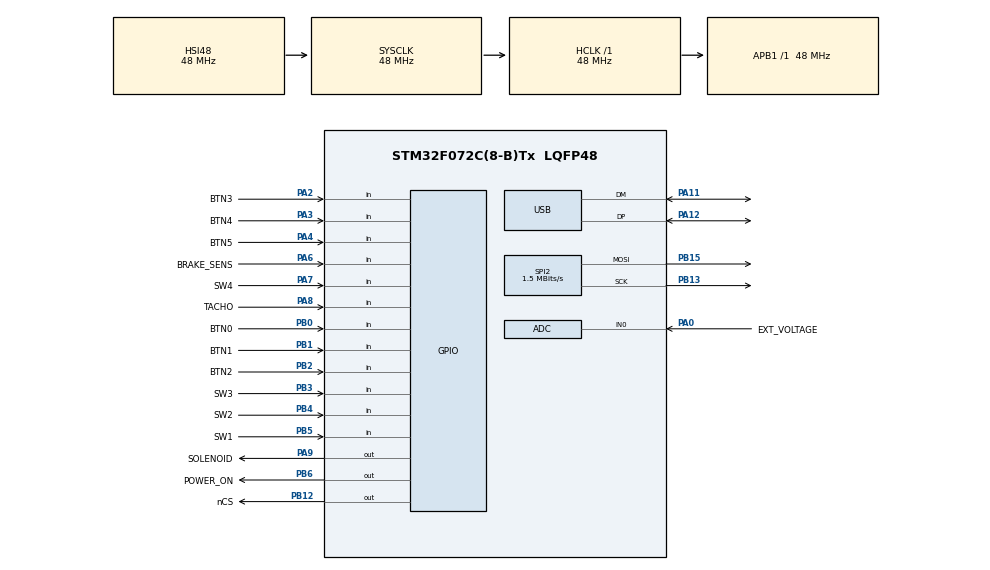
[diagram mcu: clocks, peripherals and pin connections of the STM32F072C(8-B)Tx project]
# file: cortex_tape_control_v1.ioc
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ADC.ClockPrescaler=ADC_CLOCK_ASYNC_DIV1
ADC.ContinuousConvMode=ENABLE
ADC.DMAContinuousRequests=DISABLE
ADC.DiscontinuousConvMode=DISABLE
ADC.EOCSelection=ADC_EOC_SINGLE_CONV
ADC.SamplingTime=ADC_SAMPLETIME_28CYCLES_5
Dma.ADC.0.Direction=DMA_PERIPH_TO_MEMORY
Dma.ADC.0.Instance=DMA1_Channel1
Dma.ADC.0.MemDataAlignment=DMA_MDATAALIGN_HALFWORD
Dma.ADC.0.MemInc=DMA_MINC_ENABLE
Dma.ADC.0.Mode=DMA_CIRCULAR
Dma.ADC.0.PeriphDataAlignment=DMA_PDATAALIGN_HALFWORD
Dma.ADC.0.PeriphInc=DMA_PINC_DISABLE
Dma.ADC.0.Priority=DMA_PRIORITY_LOW
Dma.Request0=ADC
Mcu.Family=STM32F0
Mcu.Name=STM32F072C(8-B)Tx
Mcu.Package=LQFP48
NVIC.DMA1_Channel1_IRQn=true\:0\:0\:false\:false\:true\:false\:true\:true
NVIC.USB_IRQn=true\:0\:0\:false\:false\:true\:false\:true\:true
PA0.GPIO_Label=EXT_VOLTAGE
PA0.Mode=IN0
PA0.Signal=ADC_IN0
PA11.Mode=Device
PA11.Signal=USB_DM
PA12.Mode=Device
PA12.Signal=USB_DP
PA13.Mode=Serial_Wire
PA13.Signal=SYS_SWDIO
PA14.Mode=Serial_Wire
PA14.Signal=SYS_SWCLK
PA2.GPIO_Label=BTN3
PA2.GPIO_PuPd=GPIO_PULLUP
PA2.Signal=GPIO_Input
PA3.GPIO_Label=BTN4
PA3.GPIO_PuPd=GPIO_PULLUP
PA3.Signal=GPIO_Input
PA4.GPIO_Label=BTN5
PA4.GPIO_PuPd=GPIO_PULLUP
PA4.Signal=GPIO_Input
PA6.GPIO_Label=BRAKE_SENS
PA6.GPIO_PuPd=GPIO_PULLUP
PA6.Signal=GPIO_Input
PA7.GPIO_Label=SW4
PA7.GPIO_PuPd=GPIO_PULLUP
PA7.Signal=GPIO_Input
PA8.GPIO_Label=TACHO
PA8.GPIO_PuPd=GPIO_PULLUP
PA8.Signal=GPIO_Input
PA9.GPIO_Label=SOLENOID
PA9.GPIO_PuPd=GPIO_PULLUP
PA9.GPIO_Speed=GPIO_SPEED_FREQ_HIGH
PA9.Signal=GPIO_Output
PB0.GPIO_Label=BTN0
PB0.GPIO_PuPd=GPIO_PULLUP
PB0.Signal=GPIO_Input
PB1.GPIO_Label=BTN1
PB1.GPIO_PuPd=GPIO_PULLUP
PB1.Signal=GPIO_Input
PB12.GPIO_Label=nCS
PB12.GPIO_PuPd=GPIO_PULLUP
PB12.PinState=GPIO_PIN_SET
PB12.Signal=GPIO_Output
PB13.Mode=TX_Only_Simplex_Unidirect_Master
PB13.Signal=SPI2_SCK
PB15.Mode=TX_Only_Simplex_Unidirect_Master
PB15.Signal=SPI2_MOSI
PB2.GPIO_Label=BTN2
PB2.GPIO_PuPd=GPIO_PULLUP
PB2.Signal=GPIO_Input
PB3.GPIO_Label=SW3
PB3.GPIO_PuPd=GPIO_PULLUP
PB3.Signal=GPIO_Input
PB4.GPIO_Label=SW2
PB4.GPIO_PuPd=GPIO_PULLUP
PB4.Signal=GPIO_Input
PB5.GPIO_Label=SW1
PB5.GPIO_PuPd=GPIO_PULLUP
PB5.Signal=GPIO_Input
PB6.GPIO_Label=POWER_ON
PB6.Signal=GPIO_Output
PF0-OSC_IN.Mode=HSE-External-Oscillator
PF0-OSC_IN.Signal=RCC_OSC_IN
PF1-OSC_OUT.Mode=HSE-External-Oscillator
PF1-OSC_OUT.Signal=RCC_OSC_OUT
ProjectManager.HeapSize=0x400
ProjectManager.StackSize=0x400
ProjectManager.TargetToolchain=Makefile
RCC.AHBFreq_Value=48000000
RCC.APB1Freq_Value=48000000
RCC.APB1TimFreq_Value=48000000
RCC.HCLKFreq_Value=48000000
RCC.PLLSourceVirtual=RCC_PLLSOURCE_HSE
RCC.RTCClockSelection=RCC_RTCCLKSOURCE_LSE
RCC.SYSCLKFreq_VALUE=48000000
RCC.SYSCLKSource=RCC_SYSCLKSOURCE_HSI48
SPI2.BaudRatePrescaler=SPI_BAUDRATEPRESCALER_32
SPI2.CLKPhase=SPI_PHASE_1EDGE
SPI2.CLKPolarity=SPI_POLARITY_HIGH
SPI2.CalculateBaudRate=1.5 MBits/s
SPI2.DataSize=SPI_DATASIZE_8BIT
SPI2.Direction=SPI_DIRECTION_2LINES
SPI2.Mode=SPI_MODE_MASTER
SPI2.VirtualType=VM_MASTER
TIM6.Prescaler=47
TIM7.Prescaler=47
USB_DEVICE.CLASS_NAME_FS=CDC
USB_DEVICE.VirtualMode=Cdc
USB_DEVICE.VirtualModeFS=Cdc_FS
VP_ADC_Vbat_Input.Mode=IN-Vbat
VP_ADC_Vref_Input.Mode=IN-Vrefint
VP_TIM6_VS_ClockSourceINT.Mode=Enable_Timer
VP_TIM7_VS_ClockSourceINT.Mode=Enable_Timer
VP_USB_DEVICE_VS_USB_DEVICE_CDC_FS.Mode=CDC_FS
board=custom

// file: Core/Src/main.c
/* USER CODE BEGIN Header */
/**
  ******************************************************************************
  * @file           : main.c
  * @brief          : Main program body
  ******************************************************************************
  * @attention
  *
  * Copyright (c) 2025 STMicroelectronics.
  * All rights reserved.
  *
  * This software is licensed under terms that can be found in the LICENSE file
  * in the root directory of this software component.
  * If no LICENSE file comes with this software, it is provided AS-IS.
  *
  ******************************************************************************
  */
/* USER CODE END Header */
#include "main.h"
#include "adc.h"
#include "dma.h"
#include "spi.h"
#include "tim.h"
#include "usb_device.h"
#include "gpio.h"

/* USER CODE BEGIN Includes */
#include "app/application.h"
#include "app/utils/itick_timer.h"
#include "app/utils/itimer.h"

#include "libs/SoftwareTimer/SoftTimers.h"
/* USER CODE END Includes */

void SystemClock_Config(void);

int main(void)
{

  /* USER CODE BEGIN 1 */
  const stimer_init_ctx_t m_timer_ctx = {
    .disable_irq = timer_irq_disable,
    .enable_irq = timer_irq_enable
  };
  /* USER CODE END 1 */

  /* MCU Configuration--------------------------------------------------------*/

  /* Reset of all peripherals, Initializes the Flash interface and the Systick. */
  HAL_Init();

  /* Configure the system clock */
  SystemClock_Config();

  /* Initialize all configured peripherals */
  MX_GPIO_Init();
  MX_DMA_Init();
  MX_SPI2_Init();
  MX_TIM7_Init();
  MX_TIM6_Init();
  MX_ADC_Init();
  MX_USB_DEVICE_Init();
  /* USER CODE BEGIN 2 */
  tt_init(&htim6);
  tt_init(&htim7);
  Timer_Init(&m_timer_ctx);
  application();
  /* USER CODE END 2 */

  /* Infinite loop */
  while (1)
  {

  }
}

void SystemClock_Config(void)
{
  RCC_OscInitTypeDef RCC_OscInitStruct = {0};
  RCC_ClkInitTypeDef RCC_ClkInitStruct = {0};
  RCC_PeriphCLKInitTypeDef PeriphClkInit = {0};

  /** Initializes the RCC Oscillators according to the specified parameters
  * in the RCC_OscInitTypeDef structure.
  */
  RCC_OscInitStruct.OscillatorType = RCC_OSCILLATORTYPE_HSI14|RCC_OSCILLATORTYPE_HSI48;
  RCC_OscInitStruct.HSI48State = RCC_HSI48_ON;
  RCC_OscInitStruct.HSI14State = RCC_HSI14_ON;
  RCC_OscInitStruct.HSI14CalibrationValue = 16;
  RCC_OscInitStruct.PLL.PLLState = RCC_PLL_NONE;
  if (HAL_RCC_OscConfig(&RCC_OscInitStruct) != HAL_OK)
  {
    Error_Handler();
  }

  /** Initializes the CPU, AHB and APB buses clocks
  */
  RCC_ClkInitStruct.ClockType = RCC_CLOCKTYPE_HCLK|RCC_CLOCKTYPE_SYSCLK
                              |RCC_CLOCKTYPE_PCLK1;
  RCC_ClkInitStruct.SYSCLKSource = RCC_SYSCLKSOURCE_HSI48;
  RCC_ClkInitStruct.AHBCLKDivider = RCC_SYSCLK_DIV1;
  RCC_ClkInitStruct.APB1CLKDivider = RCC_HCLK_DIV1;

  if (HAL_RCC_ClockConfig(&RCC_ClkInitStruct, FLASH_LATENCY_1) != HAL_OK)
  {
    Error_Handler();
  }
  PeriphClkInit.PeriphClockSelection = RCC_PERIPHCLK_USB;
  PeriphClkInit.UsbClockSelection = RCC_USBCLKSOURCE_HSI48;

  if (HAL_RCCEx_PeriphCLKConfig(&PeriphClkInit) != HAL_OK)
  {
    Error_Handler();
  }
}

void Error_Handler(void)
{
  __disable_irq();
  while (1)
  {
  }
}
